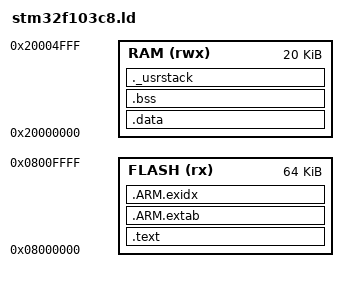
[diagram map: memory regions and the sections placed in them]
/*
Linker script for STM32F103C8_64K_20K

modified from

http://www.codesourcery.com/archives/arm-gnu/msg02972.html
http://communities.mentor.com/community/cs/archives/arm-gnu/msg02972.html
*/

/*
There will be a link error if there is not this amount of RAM free at the
end.
*/

_Minimum_Stack_Size = 256;

ENTRY(Reset_Handler)


/* Memory Spaces Definitions */

MEMORY
{
  RAM (rwx)  : ORIGIN = 0x20000000, LENGTH = 20K
  FLASH (rx) : ORIGIN = 0x08000000, LENGTH = 64K
}

__ram_start__ = ORIGIN(RAM);
__ram_size__  = LENGTH(RAM);
__ram_end__   = __ram_start__ + __ram_size__;
_estack = __ram_end__;
/* highest address of the user mode stack */



PROVIDE ( _Stack_Limit = _estack - _Minimum_Stack_Size );

/* Sections Definitions */

SECTIONS
{
    .text :
    {
        KEEP(*(.isr_vector))            /* Startup code */
        *(.text)                   /* code */
        *(.text.*)                 /* remaining code */
        *(.rodata)                 /* read-only data (constants) */
        *(.rodata.*)
        *(.glue_7)
        *(.glue_7t)
        *(.vfp11_veneer)
        *(.v4_bx)
        *(.ARM.extab* .gnu.linkonce.armextab.*)
    } >FLASH

    /* for exception handling/unwind - some Newlib functions (in
    common with C++ and STDC++) use this. */
    .ARM.extab :
    {
        *(.ARM.extab* .gnu.linkonce.armextab.*)

    } > FLASH

     __exidx_start = .;
    .ARM.exidx :
    {
        *(.ARM.exidx* .gnu.linkonce.armexidx.*)
    } > FLASH
        __exidx_end = .;

    . = ALIGN(4);
     _etext = .;
    /* This is used by the startup in order to initialize the .data secion
*/
    _sidata = _etext;

    /* This is the initialized data section
    The program executes knowing that the data is in the RAM
    but the loader puts the initial values in the FLASH (inidata).
    It is one task of the startup to copy the initial values from FLASH to
RAM. */
    .data  : AT ( _sidata )
    {
        . = ALIGN(4);
        /* This is used by the startup in order to initialize the .data
secion */
        _sdata = . ;

        *(.data)
        *(.data.*)

        . = ALIGN(4);
        /* This is used by the startup in order to initialize the .data
secion */
        _edata = . ;
    } >RAM


    /* This is the uninitialized data section */
    .bss :
    {
        . = ALIGN(4);
        /* This is used by the startup in order to initialize the .bss
secion */
        _sbss = .;
	__bss_start__ = _sbss;
        *(.bss)
        *(.bss.*)
        *(COMMON)

        . = ALIGN(4);
        /* This is used by the startup in order to initialize the .bss
secion */
        _ebss = . ;
	__bss_end__ = _ebss;
    } >RAM

    PROVIDE ( end = _ebss );
    PROVIDE ( _end = _ebss );
    PROVIDE ( _exit = _ebss );
    PROVIDE (_stackend = ORIGIN(RAM) + LENGTH(RAM) - _Minimum_Stack_Size);

    /* This is the user stack section
    This is just to check that there is enough RAM left for the User mode
stack
    It should generate an error if it's full.
     */
    ._usrstack :
    {
        . = ALIGN(4);
        _susrstack = . ;

        . = . + _Minimum_Stack_Size ;

        . = ALIGN(4);
        _eusrstack = . ;
    } >RAM



    /* after that it's only debugging information. */

    /* remove the debugging information from the standard libraries */
/*
    DISCARD :
    {
     libc.a ( * )
     libm.a ( * )
     libgcc.a ( * )
     }
*/

    /* Stabs debugging sections.  */
    .stab          0 : { *(.stab) }
    .stabstr       0 : { *(.stabstr) }
    .stab.excl     0 : { *(.stab.excl) }
    .stab.exclstr  0 : { *(.stab.exclstr) }
    .stab.index    0 : { *(.stab.index) }
    .stab.indexstr 0 : { *(.stab.indexstr) }
    .comment       0 : { *(.comment) }
    /* DWARF debug sections.
       Symbols in the DWARF debugging sections are relative to the beginning
       of the section so we begin them at 0.  */
    /* DWARF 1 */
    .debug          0 : { *(.debug) }
    .line           0 : { *(.line) }
    /* GNU DWARF 1 extensions */
    .debug_srcinfo  0 : { *(.debug_srcinfo) }
    .debug_sfnames  0 : { *(.debug_sfnames) }
    /* DWARF 1.1 and DWARF 2 */
    .debug_aranges  0 : { *(.debug_aranges) }
    .debug_pubnames 0 : { *(.debug_pubnames) }
    /* DWARF 2 */
    .debug_info     0 : { *(.debug_info .gnu.linkonce.wi.*) }
    .debug_abbrev   0 : { *(.debug_abbrev) }
    .debug_line     0 : { *(.debug_line) }
    .debug_frame    0 : { *(.debug_frame) }
    .debug_str      0 : { *(.debug_str) }
    .debug_loc      0 : { *(.debug_loc) }
    .debug_macinfo  0 : { *(.debug_macinfo) }
    /* SGI/MIPS DWARF 2 extensions */
    .debug_weaknames 0 : { *(.debug_weaknames) }
    .debug_funcnames 0 : { *(.debug_funcnames) }
    .debug_typenames 0 : { *(.debug_typenames) }
    .debug_varnames  0 : { *(.debug_varnames) }
}
